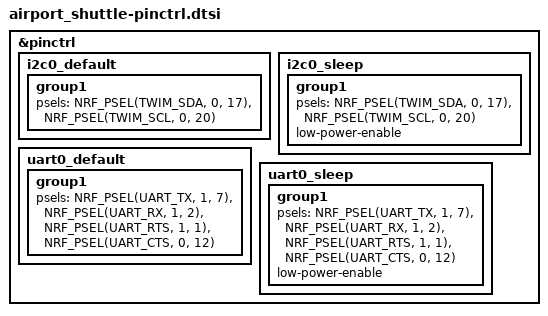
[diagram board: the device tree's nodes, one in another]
&pinctrl {
	i2c0_default: i2c0_default {
		group1 {
			psels = <NRF_PSEL(TWIM_SDA, 0, 17)>,
				<NRF_PSEL(TWIM_SCL, 0, 20)>;
		};
	};

	i2c0_sleep: i2c0_sleep {
		group1 {
			psels = <NRF_PSEL(TWIM_SDA, 0, 17)>,
				<NRF_PSEL(TWIM_SCL, 0, 20)>;
			low-power-enable;
		};
	};

	uart0_default: uart0_default {
		group1 {
			psels = <NRF_PSEL(UART_TX, 1, 7)>,
				<NRF_PSEL(UART_RX, 1, 2)>,
				<NRF_PSEL(UART_RTS, 1, 1)>,
				<NRF_PSEL(UART_CTS, 0, 12)>;
		};
	};

	uart0_sleep: uart0_sleep {
		group1 {
			psels = <NRF_PSEL(UART_TX, 1, 7)>,
				<NRF_PSEL(UART_RX, 1, 2)>,
				<NRF_PSEL(UART_RTS, 1, 1)>,
				<NRF_PSEL(UART_CTS, 0, 12)>;
			low-power-enable;
		};
	};

};
